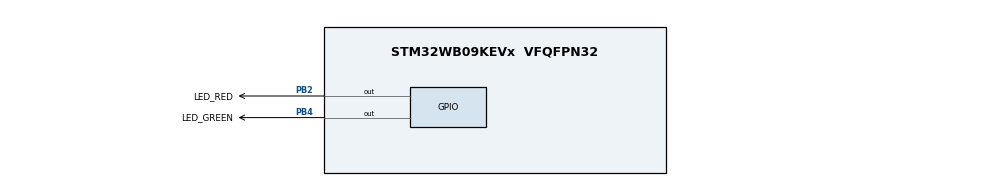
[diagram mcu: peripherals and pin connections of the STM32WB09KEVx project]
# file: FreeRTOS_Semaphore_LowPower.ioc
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FREERTOS.INCLUDE_xTaskGetSchedulerState=1
FREERTOS.Tasks01=MainThread,24,256,MainThread_Entry,Default,NULL,Dynamic,NULL,NULL
FREERTOS.configLIBRARY_MAX_SYSCALL_INTERRUPT_PRIORITY=3
FREERTOS.configTOTAL_HEAP_SIZE=4096
FREERTOS.configUSE_NEWLIB_REENTRANT=0
FREERTOS.configUSE_TICKLESS_IDLE=1
Mcu.Family=STM32WB0
Mcu.Name=STM32WB09KEVx
Mcu.Package=VFQFPN32
NVIC.TIM2_IRQn=true\:3\:0\:false\:false\:true\:false\:false\:true\:true
NVIC.TimeBase=TIM2_IRQn
NVIC.TimeBaseIP=TIM2
OSCIN.Mode=HSE-External-Oscillator
OSCIN.Signal=RCC_OSC_IN
OSCOUT.Mode=HSE-External-Oscillator
OSCOUT.Signal=RCC_OSC_OUT
PB2.GPIO_Label=LED_RED
PB2.GPIO_PuPd=GPIO_PULLUP
PB2.PinState=GPIO_PIN_SET
PB2.Signal=GPIO_Output
PB4.GPIO_Label=LED_GREEN
PB4.GPIO_PuPd=GPIO_PULLUP
PB4.PinState=GPIO_PIN_SET
PB4.Signal=GPIO_Output
ProjectManager.HeapSize=0x000
ProjectManager.StackSize=0xC00
ProjectManager.TargetToolchain=EWARM V9.30
RCC.CLKSYSMultSource=SYSCLK32Prescaler
RCC.Clk16MHzSource=CLK16MHzDiv2
RCC.Clk32MHzSource=SysCLKOutput
RCC.HSE_VALUE=32000000
RCC.HSI_VALUE=64000000
RCC.LSE_Timout=100
RCC.LSE_VALUE=32768
RCC.SYSCLK64Divider=RCC_RC64MPLL_DIV2
RCC.SYSCLKSource=RCC_SYSCLKSOURCE_DIRECT_HSE
VP_FREERTOS_VS_CMSIS_V2.Mode=CMSIS_V2
VP_MEMORYMAP_VS_MEMORYMAP.Mode=CurAppReg
VP_PWR_VS_SECSignals.Mode=Security/Privilege
VP_SYS_VS_tim2.Mode=TIM2
board=custom

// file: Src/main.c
/* USER CODE BEGIN Header */
/**
  ******************************************************************************
  * @file           : main.c
  * @brief          : Main program body
  ******************************************************************************
  * @attention
  *
  * Copyright (c) 2024 STMicroelectronics.
  * All rights reserved.
  *
  * This software is licensed under terms that can be found in the LICENSE file
  * in the root directory of this software component.
  * If no LICENSE file comes with this software, it is provided AS-IS.
  *
  ******************************************************************************
  */
/* USER CODE END Header */
#include "main.h"
#include "FreeRTOS.h"
#include "cmsis_os2.h"

/* Definitions for MainThread */
osThreadId_t MainThreadHandle;
const osThreadAttr_t MainThread_attributes = {
  .name = "MainThread",
  .stack_size = 256 * 4,
  .priority = (osPriority_t) osPriorityNormal,
};
/* USER CODE BEGIN PV */
/* Definitions for BinarySemaphore */
osSemaphoreId_t BinarySemaphoreHandle;
const osSemaphoreAttr_t BinarySemaphore_attributes = {
  .name = "BinarySemaphore"
};
/* USER CODE END PV */

void SystemClock_Config(void);
void PeriphCommonClock_Config(void);
static void MX_GPIO_Init(void);
void MainThread_Entry(void *argument);

int main(void)
{

  /* MCU Configuration--------------------------------------------------------*/

  /* Reset of all peripherals, Initializes the Flash interface and the Systick. */
  HAL_Init();

  /* Configure the system clock */
  SystemClock_Config();

  /* Configure the peripherals common clocks */
  PeriphCommonClock_Config();

  /* Initialize all configured peripherals */
  MX_GPIO_Init();

  /* Init scheduler */
  osKernelInitialize();

  /* USER CODE BEGIN RTOS_SEMAPHORES */
  /* add semaphores, ... */
  BinarySemaphoreHandle = osSemaphoreNew(1, 0, &BinarySemaphore_attributes);
  /* USER CODE END RTOS_SEMAPHORES */

  /* Create the thread(s) */
  /* creation of MainThread */
  MainThreadHandle = osThreadNew(MainThread_Entry, NULL, &MainThread_attributes);

  /* Start scheduler */
  osKernelStart();

  /* We should never get here as control is now taken by the scheduler */

  /* Infinite loop */
  while (1)
  {

  }
}

void SystemClock_Config(void)
{
  RCC_OscInitTypeDef RCC_OscInitStruct = {0};
  RCC_ClkInitTypeDef RCC_ClkInitStruct = {0};

  /** Initializes the RCC Oscillators according to the specified parameters
  * in the RCC_OscInitTypeDef structure.
  */
  RCC_OscInitStruct.OscillatorType = RCC_OSCILLATORTYPE_HSE;
  RCC_OscInitStruct.HSEState = RCC_HSE_ON;
  if (HAL_RCC_OscConfig(&RCC_OscInitStruct) != HAL_OK)
  {
    Error_Handler();
  }

  /** Configure the SYSCLKSource and SYSCLKDivider
  */
  RCC_ClkInitStruct.SYSCLKSource = RCC_SYSCLKSOURCE_DIRECT_HSE;
  RCC_ClkInitStruct.SYSCLKDivider = RCC_DIRECT_HSE_DIV1;

  if (HAL_RCC_ClockConfig(&RCC_ClkInitStruct, FLASH_WAIT_STATES_0) != HAL_OK)
  {
    Error_Handler();
  }
}

void PeriphCommonClock_Config(void)
{
  RCC_PeriphCLKInitTypeDef PeriphClkInitStruct = {0};

  /** Initializes the peripherals clock
  */
  PeriphClkInitStruct.PeriphClockSelection = RCC_PERIPHCLK_SMPS;
  PeriphClkInitStruct.SmpsDivSelection = RCC_SMPSCLK_DIV4;

  if (HAL_RCCEx_PeriphCLKConfig(&PeriphClkInitStruct) != HAL_OK)
  {
    Error_Handler();
  }
}

static void MX_GPIO_Init(void)
{
  GPIO_InitTypeDef GPIO_InitStruct = {0};

  /* GPIO Ports Clock Enable */
  __HAL_RCC_GPIOB_CLK_ENABLE();

  /*Configure GPIO pin Output Level */
  HAL_GPIO_WritePin(GPIOB, LED_RED_Pin|LED_GREEN_Pin, GPIO_PIN_SET);

  /*Configure GPIO pins : LED_RED_Pin LED_GREEN_Pin */
  GPIO_InitStruct.Pin = LED_RED_Pin|LED_GREEN_Pin;
  GPIO_InitStruct.Mode = GPIO_MODE_OUTPUT_PP;
  GPIO_InitStruct.Pull = GPIO_PULLUP;
  GPIO_InitStruct.Speed = GPIO_SPEED_FREQ_LOW;
  HAL_GPIO_Init(GPIOB, &GPIO_InitStruct);

  /**/
  HAL_PWREx_EnableGPIOPullUp(PWR_GPIO_B, PWR_GPIO_BIT_2|PWR_GPIO_BIT_4);

}

/* USER CODE BEGIN 4 */
void PreSleepProcessing(uint32_t ulExpectedIdleTime)
{
  PWR_DEEPSTOPTypeDef sConfigDEEPSTOP;
  /* LED red ON indicate the system in Deepstop mode */
  HAL_GPIO_WritePin(GPIOB, LED_RED_Pin, GPIO_PIN_RESET);

  /* Enable WakeUp Pin PWR_WAKEUP_PA0 */
  HAL_PWR_EnableWakeUpPin(PWR_WAKEUP_PA0,PWR_WUP_RISIEDG);

  /* Clear all related wakeup flags*/
  __HAL_PWR_CLEAR_FLAG(PWR_FLAG_WUF12);

  HAL_SuspendTick();

  sConfigDEEPSTOP.deepStopMode = PWR_DEEPSTOP_WITH_SLOW_CLOCK_ON;

  HAL_PWR_ConfigDEEPSTOP(&sConfigDEEPSTOP);

  /* Enter STOP mode */
  HAL_PWR_EnterDEEPSTOPMode();

}

void PostSleepProcessing(uint32_t ulExpectedIdleTime)
{
  /* Restore Clock settings */
  SystemClock_Config();

  /* Resume HAL timebase */
  HAL_ResumeTick();

  /* Semaphore Release */
  osSemaphoreRelease(BinarySemaphoreHandle);
}

/* USER CODE END 4 */

void MainThread_Entry(void *argument)
{
  /* USER CODE BEGIN 5 */
  uint8_t i = 0;
  /* Infinite loop */
    for(;;osSemaphoreAcquire(BinarySemaphoreHandle, osWaitForever))
    {
       /* LED red OFF and LED green toggle indicate the system in Run mode */
       HAL_GPIO_WritePin(GPIOB, LED_RED_Pin, GPIO_PIN_SET);
       for (i=0; i<10; i++)
       {
          HAL_GPIO_TogglePin(LED_GREEN_GPIO_Port, LED_GREEN_Pin);
          HAL_Delay(500);
       }
    }
  /* USER CODE END 5 */
}

void HAL_TIM_PeriodElapsedCallback(TIM_HandleTypeDef *htim)
{
  if (htim->Instance == TIM2)
  {
    HAL_IncTick();
  }
}

void Error_Handler(void)
{
  /* USER CODE BEGIN Error_Handler_Debug */
  /* User can add his own implementation to report the HAL error return state */
  while (1)
  {
    HAL_GPIO_TogglePin(LED_RED_GPIO_Port, LED_RED_Pin);
    HAL_Delay(500);
  }
  /* USER CODE END Error_Handler_Debug */
}
